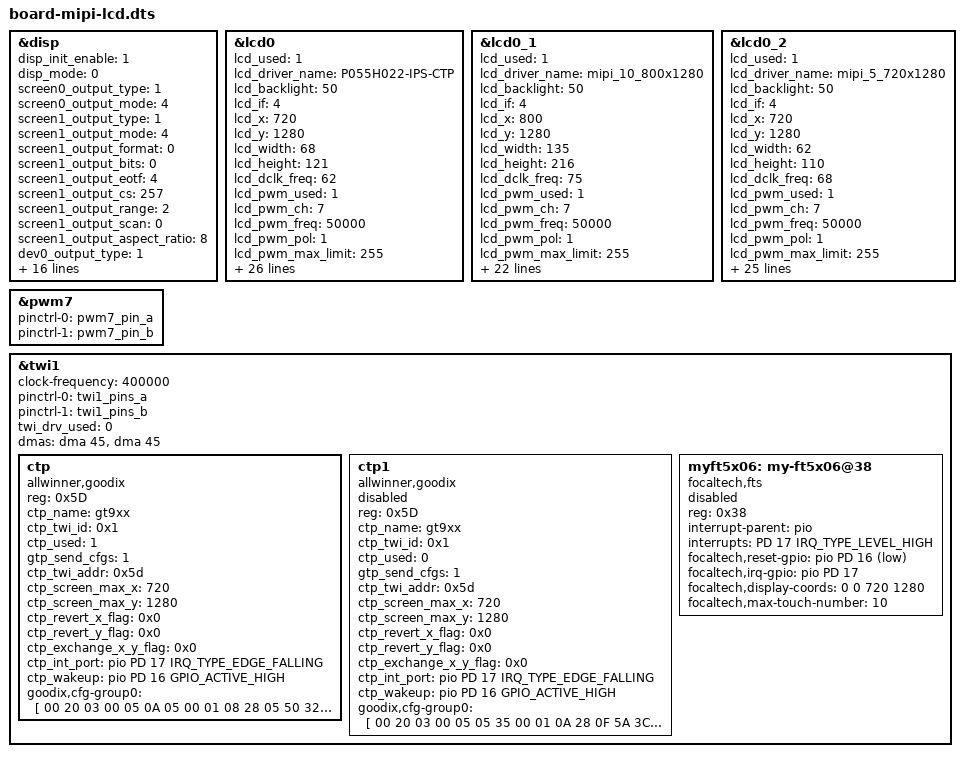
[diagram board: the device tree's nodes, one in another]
/dts-v1/;

#include "board.dts"

/*----------------------------------------------------------------------------------
disp init configuration

disp_mode             (0:screen0<screen0,fb0>)
screenx_output_type   (0:none; 1:lcd; 2:tv; 5:vdpo)
fbx format            (4:RGB655 5:RGB565 6:RGB556 7:ARGB1555 8:RGBA5551 9:RGB888 10:ARGB8888 12:ARGB4444)
fbx pixel sequence    (0:ARGB 1:BGRA 2:ABGR 3:RGBA)
fb0_scaler_mode_enable(scaler mode enable, used FE)
fbx_width,fbx_height  (framebuffer horizontal/vertical pixels, fix to output resolution while equal 0)
lcdx_backlight        (lcd init backlight,the range:[0,256],default:197
lcdx_yy               (lcd init screen bright/contrast/saturation/hue, value:0~100, default:50/50/57/50)
lcd0_contrast         (LCD contrast, 0~100)
lcd0_saturation       (LCD saturation, 0~100)
lcd0_hue              (LCD hue, 0~100)
framebuffer software rotation setting:
disp_rotation_used:   (0:disable; 1:enable,you must set fbX_width to lcd_y,
set fbX_height to lcd_x)
degreeX:              (X:screen index; 0:0 degree; 1:90 degree; 3:270 degree)
degreeX_Y:            (X:screen index; Y:layer index 0~15; 0:0 degree; 1:90 degree; 3:270 degree)
devX_output_type : config output type in bootGUI framework in UBOOT-2018.
				   (0:none; 1:lcd; 2:tv;)
devX_output_mode : config output resolution(see include/video/sunxi_display2.h) of bootGUI framework in UBOOT-2018
devX_screen_id   : config display index of bootGUI framework in UBOOT-2018
devX_do_hpd      : whether do hpd detectation or not in UBOOT-2018
chn_cfg_mode     : Hardware DE channel allocation config. 0:single display with 6
                                   channel, 1:dual display with 4 channel in main display and 2 channel in second
                   display, 2:dual display with 3 channel in main display and 3 channel in second
                   in display.
----------------------------------------------------------------------------------*/
&disp {
	disp_init_enable         = <1>;
	disp_mode                = <0>;

	screen0_output_type      = <1>;
	screen0_output_mode      = <4>;

	screen1_output_type      = <1>;
	screen1_output_mode      = <4>;

	screen1_output_format    = <0>;
	screen1_output_bits      = <0>;
	screen1_output_eotf      = <4>;
	screen1_output_cs        = <257>;
	screen1_output_range     = <2>;
	screen1_output_scan      = <0>;
	screen1_output_aspect_ratio = <8>;

	dev0_output_type         = <1>;
	dev0_output_mode         = <4>;
	dev0_screen_id           = <0>;
	dev0_do_hpd              = <0>;

	dev1_output_type         = <4>;
	dev1_output_mode         = <10>;
	dev1_screen_id           = <1>;
	dev1_do_hpd              = <1>;

	def_output_dev           = <0>;

	fb0_format               = <0>;
	fb0_width                = <720>;
	fb0_height               = <1280>;

	fb1_format               = <0>;
	fb1_width                = <0>;
	fb1_height               = <0>;
	chn_cfg_mode             = <1>;

	disp_para_zone           = <1>;
	/*VCC-LCD*/
/*	dc1sw-supply = <&reg_dc1sw>;*/
	/*VCC-DSI*/
/*	eldo3-supply = <&reg_eldo3>;*/
	/*VCC-PD*/
/*	dcdc1-supply = <&reg_dcdc1>;*/
};
/*----------------------------------------------------------------------------------
;lcd0 configuration

;lcd_if:               0:hv(sync+de); 1:8080; 2:ttl; 3:lvds; 4:dsi; 5:edp; 6:extend dsi
;lcd_hv_if             0:Parallel RGB; 8:Serial RGB; 10:Dummy RGB; 11: RGB Dummy;12:CCIR656
;lcd_hv_clk_phase      0:0 degree;1:90 degree;2:180 degree;3:270 degree
;lcd_hv_sync_polarity  0:vs low,hs low; 1:vs high,hslow; 2:vs low,hs high; 3:vs high,hs high
;lcd_hv_syuv_seq       0:YUYV; 1:YVYU; 2:UYVY; 3:VYUY
;lcd_cpu_if            0:18bit/1 cycle parallel(RGB666); 4:16bit/1cycle parallel (RGB565)
;                      6:18bit/3 cycle parallel(RGB666); 7:16bit/2cycle parallel (RGB565)
;lcd_cpu_te            0:frame auto trigger; 1:frame triggered by te rising edge; 2:frame triggered by te falling edge;
;lcd_dsi_if            0:video mode; 1: Command mode; 2:video burst mode
;lcd_dsi_te            0:frame auto trigger; 1:frame triggered by te rising edge; 2:frame triggered by te falling edge;
;lcd_x:                lcd horizontal resolution
;lcd_y:                lcd vertical resolution
;lcd_width:            width of lcd in mm
;lcd_height:           height of lcd in mm
;lcd_dclk_freq:        in MHZ unit
;lcd_pwm_freq:         in HZ unit
;lcd_pwm_pol:          lcd backlight PWM polarity
;lcd_pwm_max_limit     lcd backlight PWM max limit(<=255)
;lcd_hbp:              hsync back porch(pixel) + hsync plus width(pixel);
;lcd_ht:               hsync total cycle(pixel)
;lcd_vbp:              vsync back porch(line) + vysnc plus width(line)
;lcd_vt:               vysnc total cycle(line)
;lcd_hspw:             hsync plus width(pixel)
;lcd_vspw:             vysnc plus width(pixel)
;lcd_lvds_if:          0:single link;  1:dual link
;lcd_lvds_colordepth:  0:8bit; 1:6bit
;lcd_lvds_mode:        0:NS mode; 1:JEIDA mode
;lcd_frm:              0:disable; 1:enable rgb666 dither; 2:enable rgb656 dither
;lcd_io_phase:         0:noraml; 1:intert phase(0~3bit: vsync phase; 4~7bit:hsync phase;
;                      8~11bit:dclk phase; 12~15bit:de phase)
;lcd_gamma_en          lcd gamma correction enable
;lcd_bright_curve_en   lcd bright curve correction enable
;lcd_cmap_en           lcd color map function enable
;deu_mode              0:smoll lcd screen; 1:large lcd screen(larger than 10inch)
;lcdgamma4iep:         Smart Backlight parameter, lcd gamma vale * 10;
;                      decrease it while lcd is not bright enough; increase while lcd is too bright
;smart_color           90:normal lcd screen 65:retina lcd screen(9.7inch)
;Pin setting for special function ie.LVDS, RGB data or vsync
;   name(donot care) = port:PD12<pin function><pull up or pull down><drive ability><output level>
;Pin setting for gpio:
;   lcd_gpio_X     = port:PD12<pin function><pull up or pull down><drive ability><output level>
;Pin setting for backlight enable pin
;   lcd_bl_en     = port:PD12<pin function><pull up or pull down><drive ability><output level>
;fsync setting, pulse to csi
;lcd_fsync_en          (0:disable fsync,1:enable)
;lcd_fsync_act_time    (active time of fsync, unit:pixel)
;lcd_fsync_dis_time    (disactive time of fsync, unit:pixel)
;lcd_fsync_pol         (0:positive;1:negative)
;gpio config: <&pio for cpu or &r_pio for cpus, port, port num, pio function,
pull up or pull down(default 0), driver level(default 1), data>
;For dual link lvds: use lvds2link_pins_a  and lvds2link_pins_b instead
;For rgb24: use rgb24_pins_a  and rgb24_pins_b instead
;For lvds1: use lvds1_pins_a  and lvds1_pins_b instead
;For lvds0: use lvds0_pins_a  and lvds0_pins_b instead
;----------------------------------------------------------------------------------*/

&lcd0 {
	lcd_used            = <1>;

	lcd_driver_name     = "P055H022-IPS-CTP";
	lcd_backlight       = <50>;
	lcd_if              = <4>;

	lcd_x               = <720>;
	lcd_y               = <1280>;
	lcd_width           = <68>;
	lcd_height          = <121>;
	lcd_dclk_freq       = <62>;

	lcd_pwm_used        = <1>;
	lcd_pwm_ch          = <7>;
	lcd_pwm_freq        = <50000>;
	lcd_pwm_pol         = <1>;
	lcd_pwm_max_limit   = <255>;

	/* HX8394F panel porch (spec): HBP 40 / HFP 20 / HSW 4,
	 *                            VBP 25 / VFP 9 / VSW 2
	 * Allwinner's lcd_hbp / lcd_vbp INCLUDE the sync width -> 44 / 27,
	 * ht = 720+44+20 = 784, vt = 1280+27+9 = 1316.
	 * Identical to the A133 (kickpi-k5c) dtsi that lights this panel. */
	lcd_hbp             = <44>;
	lcd_ht              = <784>;
	lcd_hspw            = <4>;
	lcd_vbp             = <27>;
	lcd_vt              = <1316>;
	lcd_vspw            = <2>;

	lcd_dsi_lane        = <4>;
	lcd_dsi_if          = <0>;
	lcd_dsi_format      = <0>;
	lcd_dsi_te          = <0>;
	lcd_dsi_eotp        = <0>;
	lcd_frm             = <0>;
	lcd_io_phase        = <0>;
	lcd_gamma_en        = <0>;
	lcd_bright_curve_en = <0>;
	lcd_cmap_en         = <0>;

	deu_mode            = <0>;
	lcdgamma4iep        = <22>;
	smart_color         = <90>;

	lcd_pin_power  = "dcdc1";
	lcd_pin_power1 = "eldo3";

	lcd_power = "dc1sw";

	/* panel reset */
	lcd_gpio_0 = <&pio PD 21 GPIO_ACTIVE_HIGH>;
	/* power / backlight enable */
	lcd_gpio_1 = <&pio PD 18 GPIO_ACTIVE_HIGH>;

	pinctrl-0 = <&dsi4lane_pins_a>;
	pinctrl-1 = <&dsi4lane_pins_b>;
};

&lcd0_1 {
	lcd_used            = <1>;
	lcd_driver_name     = "mipi_10_800x1280";
	lcd_backlight       = <50>;
	lcd_if              = <4>;

	lcd_x               = <800>;
	lcd_y               = <1280>;
	lcd_width           = <135>;
	lcd_height          = <216>;
	lcd_dclk_freq       = <75>;

	lcd_pwm_used        = <1>;
	lcd_pwm_ch          = <7>;
	lcd_pwm_freq        = <50000>;
	lcd_pwm_pol         = <1>;
	lcd_pwm_max_limit   = <255>;

	lcd_hbp             = <88>;
	lcd_ht              = <960>;
	lcd_hspw            = <4>;
	lcd_vbp             = <12>;
	lcd_vt              = <1300>;
	lcd_vspw            = <4>;

	lcd_dsi_lane        = <4>;
	lcd_dsi_if          = <0>;
	lcd_dsi_format      = <0>;
	lcd_dsi_te          = <0>;
	lcd_dsi_eotp        = <0>;
	lcd_frm             = <0>;
	lcd_gamma_en        = <0>;
	lcd_bright_curve_en = <0>;
	lcd_cmap_en         = <0>;

	deu_mode            = <0>;
	lcdgamma4iep        = <22>;
	smart_color         = <90>;


	lcd_bl_en  = <&pio PD 18 GPIO_ACTIVE_HIGH>;
	lcd_gpio_0 = <&pio PD 21 GPIO_ACTIVE_HIGH>;
	pinctrl-0 = <&dsi4lane_pins_a>;
	pinctrl-1 = <&dsi4lane_pins_b>;
};

&lcd0_2{
	lcd_used            = <1>;

	lcd_driver_name     = "mipi_5_720x1280";
	lcd_backlight       = <50>;
	lcd_if              = <4>;

	lcd_x               = <720>;
	lcd_y               = <1280>;
	lcd_width           = <62>;
	lcd_height          = <110>;
	lcd_dclk_freq       = <68>;

	lcd_pwm_used        = <1>;
	lcd_pwm_ch          = <7>;
	lcd_pwm_freq        = <50000>;
	lcd_pwm_pol         = <1>;
	lcd_pwm_max_limit   = <255>;

	lcd_hbp             = <47>;
	lcd_ht              = <782>;
	lcd_hspw            = <15>;
	lcd_vbp             = <27>;
	lcd_vt              = <1322>;
	lcd_vspw            = <15>;

	lcd_frm             = <0>;
	lcd_gamma_en        = <0>;
	lcd_bright_curve_en = <0>;
	lcd_cmap_en         = <0>;

	deu_mode            = <0>;
	lcdgamma4iep        = <22>;
	smart_color         = <90>;

	lcd_dsi_if          = <0>;
	lcd_dsi_lane        = <4>;
	lcd_dsi_format      = <0>;
	lcd_dsi_te          = <0>;
	lcd_dsi_eotp        = <0>;	

	lcd_pin_power = "dcdc1";
	lcd_pin_power1 = "eldo3";
	//lcd_pin_power2 = "dldo2";

	lcd_power = "dc1sw";
	// lcd_bl_en = <&pio PD 21 1 0 3 1>;

	// reset
	lcd_gpio_0 = <&pio PD 21 GPIO_ACTIVE_HIGH>;
	// power
	lcd_gpio_1 = <&pio PD 18 GPIO_ACTIVE_HIGH>;

	pinctrl-0 = <&dsi4lane_pins_a>;
	pinctrl-1 = <&dsi4lane_pins_b>;

};


&pwm7 {
        status = "okay";
        pinctrl-names = "active", "sleep";
        pinctrl-0 = <&pwm7_pin_a>;
        pinctrl-1 = <&pwm7_pin_b>;
};

&twi1 {
        clock-frequency = <400000>;
        pinctrl-0 = <&twi1_pins_a>;
        pinctrl-1 = <&twi1_pins_b>;
        pinctrl-names = "default", "sleep";
        twi_drv_used = <0>;
        dmas = <&dma 45>, <&dma 45>;
        dma-names = "tx", "rx";
        status = "okay";

	ctp {
		compatible = "allwinner,goodix";
		device_type = "ctp";
		reg = <0x5D>;
		status = "okay";
		ctp_name = "gt9xx";
		ctp_twi_id = <0x1>;
		ctp_used = <1>;
		gtp_send_cfgs = <1>;
		ctp_twi_addr = <0x5d>;
		ctp_screen_max_x = <720>;
		ctp_screen_max_y = <1280>;
		ctp_revert_x_flag = <0x0>;
		ctp_revert_y_flag = <0x0>;
		ctp_exchange_x_y_flag = <0x0>;
		ctp_int_port = <&pio PD 17 IRQ_TYPE_EDGE_FALLING>;
		ctp_wakeup = <&pio PD 16 GPIO_ACTIVE_HIGH>;
		/*ctp-supply = <&reg_aldo2>;*/
		/*ctp_power_ldo = <&reg_aldo2>;*/
		/*ctp_power_ldo_vol = <3300>;*/
		goodix,cfg-group0 = [
			00 20 03 00 05 0A 05 00 01 08
			28 05 50 32 03 05 00 00 00 00
			00 00 00 00 00 00 00 8B 2B 0E
			17 15 31 0D 00 00 01 BB 03 2D
			00 00 00 00 00 03 64 32 00 00
			00 0F 23 94 C5 02 07 00 00 04
			A0 10 00 8B 13 00 7C 16 00 6A
			1B 00 5E 20 00 5E 00 00 00 00
			00 00 00 00 00 00 00 00 00 00
			00 00 00 00 00 00 00 00 00 00
			00 00 00 00 00 00 00 00 00 00
			00 00 1C 1A 18 16 14 12 10 0E
			0C 0A 08 06 04 02 00 00 00 00
			00 00 00 00 00 00 00 00 00 00
			00 00 00 02 04 06 08 0A 0C 0F
			10 12 13 16 26 24 22 21 20 1F
			1E 1D 1C 18 FF FF FF FF 00 00
			00 00 00 00 00 00 00 00 00 00
			00 00 00 00 F0 01
			];
		};

	ctp1 {
		compatible = "allwinner,goodix";
		device_type = "ctp";
		reg = <0x5D>;
		status = "disabled";
		ctp_name = "gt9xx";
		ctp_twi_id = <0x1>;
		ctp_used = <0>;
		gtp_send_cfgs = <1>;
		ctp_twi_addr = <0x5d>;
		ctp_screen_max_x = <720>;
		ctp_screen_max_y = <1280>;
		ctp_revert_x_flag = <0x0>;
		ctp_revert_y_flag = <0x0>;
		ctp_exchange_x_y_flag = <0x0>;
		ctp_int_port = <&pio PD 17 IRQ_TYPE_EDGE_FALLING>;
		ctp_wakeup = <&pio PD 16 GPIO_ACTIVE_HIGH>;
		/*ctp-supply = <&reg_aldo2>;*/
		/*ctp_power_ldo = <&reg_aldo2>;*/
		/*ctp_power_ldo_vol = <3300>;*/
		goodix,cfg-group0 = [
			00 20 03 00 05 05 35 00 01 0A
			28 0F 5A 3C 03 05 00 00 00 00
			00 00 06 18 1A 1E 14 8C 2E 0E
			B0 B2 B2 04 00 00 00 98 02 1C
			00 01 00 00 00 03 64 32 00 00
			00 A0 F5 94 D5 02 07 00 00 04
			83 A7 00 7E B5 00 78 C6 00 73
			D7 00 6F EA 00 6F 00 00 00 00
			00 00 00 00 00 00 00 00 00 00
			00 00 00 00 00 00 00 00 00 00
			00 00 00 00 00 00 00 00 00 00
			00 00 1C 1A 18 16 14 12 10 0E
			0C 0A 08 06 04 02 FF FF FF FF
			FF FF FF FF FF FF FF FF FF FF
			FF FF 00 02 04 06 08 0A 0C 0F
			10 12 13 14 16 2A 29 28 26 24
			22 21 20 1F 1E 1D 1C 18 FF FF
			FF FF FF FF FF FF FF FF FF FF
			FF FF FF FF FC 01
			];
		};

    myft5x06: my-ft5x06@38 {
        compatible = "focaltech,fts";
        status = "disabled"; /* GT9XX and FT5X06 cannot be turned on together Otherwise, GT9XX will have abnormal touch */
        reg = <0x38>;
        interrupt-parent = <&pio>;
        interrupts = <PD 17 IRQ_TYPE_LEVEL_HIGH>;
        focaltech,reset-gpio = <&pio PD 16 GPIO_ACTIVE_LOW>;
        focaltech,irq-gpio = <&pio PD 17 IRQ_TYPE_LEVEL_HIGH>;
        focaltech,display-coords = <0 0 720 1280>;
        focaltech,max-touch-number = <10>;
    };

};
